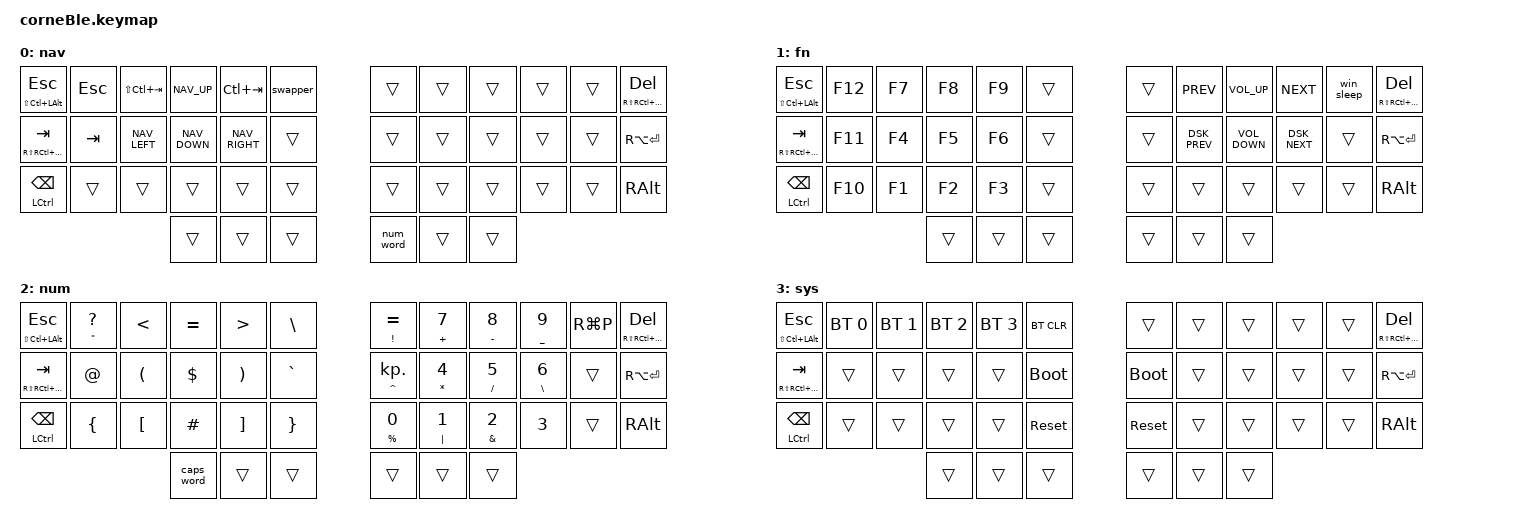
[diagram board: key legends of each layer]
/* source keypos definitions */
#include "../zmk-nodefree-config/keypos_def/keypos_42keys.h"

/* map 6 extra keys */
#define X_LT  &mt LS(LC(LALT)) ESC
#define X_LM  &mt RS(RC(RA(RGUI))) TAB
#define X_LB  &mt LCTRL BSPC

#define X_RT  &mt RS(RC(RA(RGUI))) DEL
#define X_RM  &kp RA(RET)
#define X_RB  &kp RALT

/* use 6-column layout*/
/ { chosen { zmk,matrix_transform = &default_transform; }; };

#include "../zmk-nodefree-config/helper.h"
#include "extra_keys.h"

#define XXX &none
#define ___ &trans

/* Global settings */

#define QUICK_TAP_MS 175

&sk {  // sticky-key config
    release-after-ms = <900>;  // release after 0.6s
    quick-release;             // no double capitalization when rolling keys
};

&sl {  // sticky-layer config
    ignore-modifiers;          // allow chording sticky mods & layers
};

&lt {  // layer-tap config
    flavor = "balanced";
    tapping-term-ms = <200>;
    quick-tap-ms = <QUICK_TAP_MS>;
};

/* Custom behaviors */

// Alt+Tab swapper, requires PR #1366
ZMK_BEHAVIOR(swapper, tri_state,
    bindings = <&kt LGUI>, <&kp TAB>, <&kt LGUI>;
    ignored-key-positions = <LT2>;
)

ZMK_BEHAVIOR(comma_dance, tap_dance,
    tapping-term-ms = <200>;
    bindings = <&mt SEMI COMMA>, <&kp BSLH>;
)
ZMK_BEHAVIOR(dot_dance, tap_dance,
    tapping-term-ms = <200>;
    bindings = <&mt COLON DOT>, <&kp EXCL>;
)
ZMK_BEHAVIOR(qt_dance, tap_dance,
    tapping-term-ms = <200>;
    bindings = <&mt DQT QMARK>, <&kp SQT>;
)
ZMK_BEHAVIOR(hyper_dance, tap_dance,
    tapping-term-ms = <200>;
    bindings = <&mt RS(RC(RA(RGUI))) RS(RC(RA(H)))>, <&kp RS(RC(RA(J)))>;
)

ZMK_BEHAVIOR(nayeon, macro,
    wait-ms = <0>;
    tap-ms = <5>;
    bindings = <&kp N &kp A &kp Y &kp E &kp O &kp N &kp RET>;
)

#define DEF 0
#define NAV 1
#define FN 2
#define NUM 3
#define SYS 4

/* Keymap */

ZMK_CONDITIONAL_LAYER(NAV FN, SYS)  // FN + NAV --> SYS

ZMK_LAYER(base,
//╭──────╮ ╭─────────────┬─────────────┬─────────────┬─────────────┬─────────────╮ ╭──────╮ ╭─────────────┬─────────────┬─────────────┬─────────────┬─────────────╮ ╭──────╮
    X_LT     &kp Q         &kp W         &kp E         &kp R         &kp T                    &kp Y         &kp U         &kp I         &kp O         &lt FN P        X_RT
//├──────┤ ├─────────────┼─────────────┼─────────────┼─────────────┼─────────────┤ ├──────┤ ├─────────────┼─────────────┼─────────────┼─────────────┼─────────────┤ ├──────┤
    X_LM     &mt LG(A) A  &hmr LALT S    &hmr LGUI D   &mt LG(F) F   &kp G                    &kp H         &kp J         &kp K         &kp L         &kp RET         X_RM
//├──────┤ ├─────────────┼─────────────┼─────────────┼─────────────┼─────────────┤ ├──────┤ ├─────────────┼─────────────┼─────────────┼─────────────┼─────────────┤ ├──────┤
    X_LB     &kp Z         &mt LG(X) X   &mt LG(C) C   &mt LG(V) V   &mt LS(LC(LA(V))) B      &kp N         &kp M         &comma_dance  &dot_dance    &qt_dance       X_RB
//├──────┤ ╰─────────────┼─────────────┴─────────────┼─────────────┼─────────────┤ ├──────┤ ├─────────────┼─────────────┼─────────────┴───────────────────────────╯ ├──────┤
                                         &kp LSHFT     &sk LGUI      &lt NAV SPC              &lt NUM SPC   &bs_del      &hyper_dance 
//                                     ╰────────────┼──────────────┴─────────────╯ ╰──────╯ ╰─────────────┴─────────────┼─────────────╯
)

ZMK_LAYER(nav,
//╭──────╮ ╭─────────────┬─────────────┬─────────────┬─────────────┬─────────────╮ ╭──────╮ ╭─────────────┬─────────────┬─────────────┬─────────────┬─────────────╮ ╭──────╮
    X_LT     &kp ESC      &kp LS(LC(TAB))  NAV_UP     &kp LC(TAB)    &swapper                 ___           ___     ___           ___            ___            X_RT
//├──────┤ ├─────────────┼─────────────┼─────────────┼─────────────┼─────────────┤ ├──────┤ ├─────────────┼─────────────┼─────────────┼─────────────┼─────────────┤ ├──────┤
    X_LM     &kp TAB       NAV_LEFT      NAV_DOWN      NAV_RIGHT     ___                      ___           ___           ___           ___            ___            X_RM
//├──────┤ ├─────────────┼─────────────┼─────────────┼─────────────┼─────────────┤ ├──────┤ ├─────────────┼─────────────┼─────────────┼─────────────┼─────────────┤ ├──────┤
    X_LB     ___           ___           ___           ___           ___                      ___           ___           ___           ___        ___                X_RB
//├──────┤ ╰─────────────┼─────────────┴─────────────┼─────────────┼─────────────┤ ├──────┤ ├─────────────┼─────────────┼─────────────┴───────────────────────────╯ ├──────┤
    ___                                                ___           ___                      &num_word     ___                                                       ___
//╰──────╯                                           ╰─────────────┴─────────────╯ ╰──────╯ ╰─────────────┴─────────────╯                                           ╰──────╯
)

ZMK_LAYER(fn,
//╭──────╮ ╭─────────────┬─────────────┬─────────────┬─────────────┬─────────────╮ ╭──────╮ ╭─────────────┬─────────────┬─────────────┬─────────────┬─────────────╮ ╭──────╮
    X_LT     &kp F12       &kp F7        &kp F8        &kp F9        ___                      ___           &kp C_PREV    &kp C_VOL_UP  &kp C_NEXT    &win_sleep      X_RT
//├──────┤ ├─────────────┼─────────────┼─────────────┼─────────────┼─────────────┤ ├──────┤ ├─────────────┼─────────────┼─────────────┼─────────────┼─────────────┤ ├──────┤
    X_LM     &kp F11       &kp F4        &kp F5        &kp F6        ___                      ___           DSK_PREV      VOL_DOWN      DSK_NEXT      ___             X_RM
//├──────┤ ├─────────────┼─────────────┼─────────────┼─────────────┼─────────────┤ ├──────┤ ├─────────────┼─────────────┼─────────────┼─────────────┼─────────────┤ ├──────┤
    X_LB     &kp F10       &kp F1        &kp F2        &kp F3        ___                      ___           ___           ___           ___           ___             X_RB
//├──────┤ ╰─────────────┼─────────────┴─────────────┼─────────────┼─────────────┤ ├──────┤ ├─────────────┼─────────────┼─────────────┴───────────────────────────╯ ├──────┤
    ___                                                ___           ___                      ___           ___                                                  ___
//╰──────╯                                           ╰─────────────┴─────────────╯ ╰──────╯ ╰─────────────┴─────────────╯                                           ╰──────╯
)

ZMK_LAYER(num,
//╭──────╮ ╭─────────────┬─────────────┬─────────────┬─────────────┬─────────────╮ ╭──────╮ ╭─────────────┬─────────────┬─────────────┬─────────────┬─────────────╮ ╭──────╮
    X_LT     &mt DQT QMARK &kp LT        &kp EQUAL     &kp GT        &kp BSLH               &mt EXCL EQUAL  &mt PLUS N7 &mt MINUS N8   &mt UNDER N9  &kp RG(P)     X_RT
//├──────┤ ├─────────────┼─────────────┼─────────────┼─────────────┼─────────────┤ ├──────┤ ├─────────────┼─────────────┼─────────────┼─────────────┼─────────────┤ ├──────┤
    X_LM     &kp AT        &kp LPAR      &kp DLLR      &kp RPAR      &kp GRAVE               &mt CARET KP_DOT &mt STAR N4  &mt FSLH N5  &mt BSLH N6   ___           X_RM
//├──────┤ ├─────────────┼─────────────┼─────────────┼─────────────┼─────────────┤ ├──────┤ ├─────────────┼─────────────┼─────────────┼─────────────┼─────────────┤ ├──────┤
    X_LB     &kp LBRC      &kp LBKT      &kp HASH      &kp RBKT      &kp RBRC                &mt PRCNT N0   &mt PIPE N1   &mt AMPS N2   &kp N3        ___           X_RB
//├──────┤ ╰─────────────┼─────────────┴─────────────┼─────────────┼─────────────┤ ├──────┤ ├─────────────┼─────────────┼─────────────┴───────────────────────────╯ ├──────┤
                                         &caps_word    ___           ___                      ___           ___                                                       ___
//                                     ╰─────────────┴─────────────┴─────────────╯ ╰──────╯ ╰─────────────┴─────────────╯                                           ╰──────╯
)

ZMK_LAYER(sys,
//╭──────╮ ╭─────────────┬─────────────┬─────────────┬─────────────┬─────────────╮ ╭──────╮ ╭─────────────┬─────────────┬─────────────┬─────────────┬─────────────╮ ╭──────╮
    X_LT    &bt BT_SEL 0   &bt BT_SEL 1  &bt BT_SEL 2  &bt BT_SEL 3   &bt BT_CLR              ___           ___           ___           ___           ___             X_RT
//├──────┤ ├─────────────┼─────────────┼─────────────┼─────────────┼─────────────┤ ├──────┤ ├─────────────┼─────────────┼─────────────┼─────────────┼─────────────┤ ├──────┤
    X_LM     ___           ___           ___           ___           &bootloader              &bootloader   ___           ___           ___           ___             X_RM
//├──────┤ ├─────────────┼─────────────┼─────────────┼─────────────┼─────────────┤ ├──────┤ ├─────────────┼─────────────┼─────────────┼─────────────┼─────────────┤ ├──────┤
    X_LB     ___           ___           ___           ___           &sys_reset               &sys_reset    ___           ___           ___           ___             X_RB
//├──────┤ ╰─────────────┼─────────────┴─────────────┼─────────────┼─────────────┤ ├──────┤ ├─────────────┼─────────────┼─────────────┴───────────────────────────╯ ├──────┤
    ___                                                ___           ___                      ___           ___                                                       ___
//╰──────╯                                           ╰─────────────┴─────────────╯ ╰──────╯ ╰─────────────┴─────────────╯                                           ╰──────╯
)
